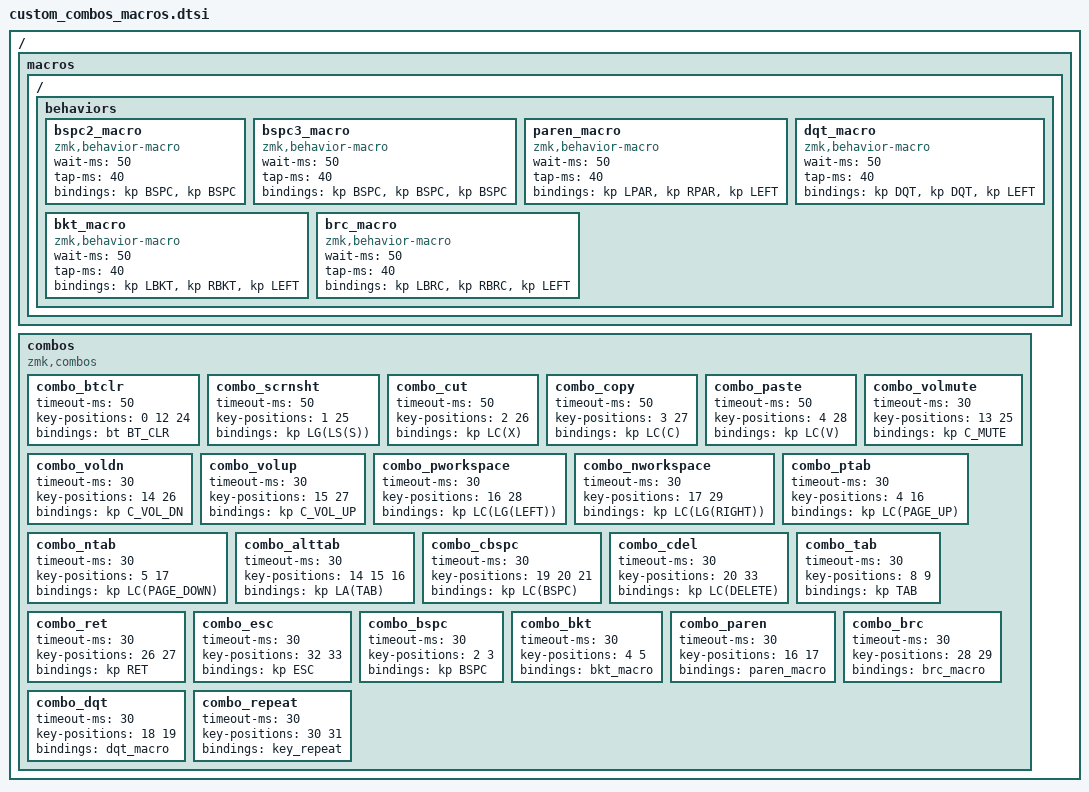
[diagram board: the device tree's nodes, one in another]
/ {
  macros {
      ZMK_MACRO(bspc2_macro,
          wait-ms = <50>;
          tap-ms = <40>;
          bindings = <&kp BSPC &kp BSPC>;
      )
      ZMK_MACRO(bspc3_macro,
          wait-ms = <50>;
          tap-ms = <40>;
          bindings = <&kp BSPC &kp BSPC &kp BSPC>;
      )
      ZMK_MACRO(paren_macro,
          wait-ms = <50>;
          tap-ms = <40>;
          bindings = <&kp LPAR &kp RPAR &kp LEFT>;
      )
      ZMK_MACRO(bkt_macro,
          wait-ms = <50>;
          tap-ms = <40>;
          bindings = <&kp LBKT &kp RBKT &kp LEFT>;
      )
      ZMK_MACRO(brc_macro,
          wait-ms = <50>;
          tap-ms = <40>;
          bindings = <&kp LBRC &kp RBRC &kp LEFT>;
      )
      ZMK_MACRO(dqt_macro,
          wait-ms = <50>;
          tap-ms = <40>;
          bindings = <&kp DQT &kp DQT &kp LEFT>;
      )
  };

  combos {

    compatible = "zmk,combos";

    combo_btclr {
        timeout-ms = <50>;
        key-positions = <0 12 24>;
        bindings = <&bt BT_CLR>;
    };

    combo_scrnsht {
        timeout-ms = <50>;
        key-positions = <1 25>;
        bindings = <&kp LG(LS(S))>;
    };

    combo_cut {
        timeout-ms = <50>;
        key-positions = <2 26>;
        bindings = <&kp LC(X)>;
    };

    combo_copy {
        timeout-ms = <50>;
        key-positions = <3 27>;
        bindings = <&kp LC(C)>;
    };

    combo_paste {
        timeout-ms = <50>;
        key-positions = <4 28>;
        bindings = <&kp LC(V)>;
    };

    combo_volmute {
        timeout-ms = <30>;
        key-positions = <13 25>;
        bindings = <&kp C_MUTE>;
    };

    combo_voldn {
        timeout-ms = <30>;
        key-positions = <14 26>;
        bindings = <&kp C_VOL_DN>;
    };

    combo_volup {
        timeout-ms = <30>;
        key-positions = <15 27>;
        bindings = <&kp C_VOL_UP>;
    };

    combo_pworkspace {
        timeout-ms = <30>;
        key-positions = <16 28>;
        bindings = <&kp LC(LG(LEFT))>;
    };

    combo_nworkspace {
        timeout-ms = <30>;
        key-positions = <17 29>;
        bindings = <&kp LC(LG(RIGHT))>;
    };

    combo_ptab {
        timeout-ms = <30>;
        key-positions = <4 16>;
        bindings = <&kp LC(PAGE_UP)>;
    };

    combo_ntab {
        timeout-ms = <30>;
        key-positions = <5 17>;
        bindings = <&kp LC(PAGE_DOWN)>;
    };

    combo_alttab {
        timeout-ms = <30>;
        key-positions = <14 15 16>;
        bindings = <&kp LA(TAB)>;
    };

    combo_cbspc {
        timeout-ms = <30>;
        key-positions = <19 20 21>;
        bindings = <&kp LC(BSPC)>;
    };

    combo_cdel {
        timeout-ms = <30>;
        key-positions = <20 33>;
        bindings = <&kp LC(DELETE)>;
    };

    combo_tab {
        timeout-ms = <30>;
        key-positions = <8 9>;
        bindings = <&kp TAB>;
    };

    combo_ret {
        timeout-ms = <30>;
        key-positions = <26 27>;
        bindings = <&kp RET>;
    };

    combo_esc {
        timeout-ms = <30>;
        key-positions = <32 33>;
        bindings = <&kp ESC>;
    };

    combo_bspc {
        timeout-ms = <30>;
        key-positions = <2 3>;
        bindings = <&kp BSPC>;
    };

    combo_bkt {
        timeout-ms = <30>;
        key-positions = <4 5>;
        bindings = <&bkt_macro>;
    };

    combo_paren {
        timeout-ms = <30>;
        key-positions = <16 17>;
        bindings = <&paren_macro>;
    };

    combo_brc {
        timeout-ms = <30>;
        key-positions = <28 29>;
        bindings = <&brc_macro>;
    };

    combo_dqt {
        timeout-ms = <30>;
        key-positions = <18 19>;
        bindings = <&dqt_macro>;
    };

    combo_repeat {
        timeout-ms = <30>;
        key-positions = <30 31>;
        bindings = <&key_repeat>;
    };
  };
};
